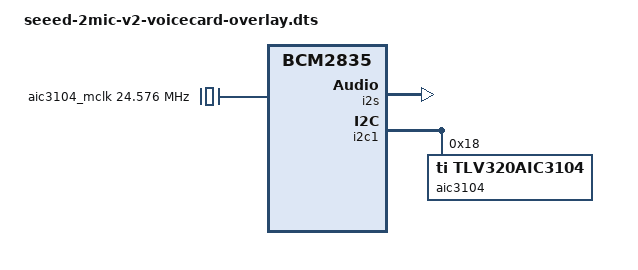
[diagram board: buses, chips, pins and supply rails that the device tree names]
/dts-v1/;
/plugin/;

/*
 * ReSpeaker 2-Mics Pi HAT v2.0 - kernel-independent device tree overlay.
 *
 * The v2 board swapped the WM8960 for a TI TLV320AIC3104 codec on i2c1 at
 * address 0x18 with a 24.576 MHz master clock. Like the v1 overlay, this
 * uses only mainline kernel drivers:
 *   - snd-soc-simple-card    (compatible = "simple-audio-card")
 *   - snd-soc-tlv320aic3x    (compatible = "ti,tlv320aic3104")
 * No out-of-tree kernel module is required, so this works on any kernel
 * >= 5.4 that ships those two modules.
 *
 * Structure follows the v1 overlay (seeed-2mic-voicecard-overlay.dts):
 * new top-level sound node (the Pi's onboard audio keeps working),
 * label-targeted &i2s / &i2c1 so it applies to any base tree exposing
 * __symbols__. Card name is identical ("seeed-2mic-voicecard" -> ALSA
 * card ID "seeed2micvoicec"), so configs and docs are shared between
 * the two HAT versions.
 *
 * CLOCK PLACEMENT NOTE - this is deliberately the OPPOSITE of v1:
 * the tlv320aic3x driver does NOT fetch a clock itself (no
 * devm_clk_get); it receives its sysclk through the set_sysclk DAI op,
 * which simple-card drives from the "clocks" property on the
 * simple-audio-card,codec dai-link subnode. On the v1 wm8960 the clock
 * had to live on the codec device node instead, because that driver
 * reads it with devm_clk_get at probe. Getting this backwards is what
 * caused "No MCLK configured" on v1 - hence this comment.
 *
 * Derived from Seeed Studio's respeaker-2mic-v2_0 overlay (MIT license,
 * Copyright (C) 2024 Seeed Studio) but restructured onto the v1
 * skeleton: Seeed's original replaces the base tree's &sound node
 * (the onboard HDMI audio node), which is unnecessary and risks
 * clobbering onboard audio; it also targets the i2s_clk_consumer
 * symbol, which is just an alias label on the same i2s node this
 * overlay targets.
 *
 * Compile:
 *   dtc -@ -I dts -O dtb -o seeed-2mic-v2-voicecard.dtbo \
 *       seeed-2mic-v2-voicecard-overlay.dts
 */
/ {
	compatible = "brcm,bcm2835";

	/* BCM2835 I2S (PCM) controller, same as v1. The codec is
	 * bitclock/frame master here, so the CPU side runs as clock
	 * consumer - same node either way. */
	fragment@0 {
		target = <&i2s>;
		__overlay__ {
			status = "okay";
		};
	};

	/* Codec master clock: 24.576 MHz fixed clock, referenced from the
	 * dai-link codec subnode below (see CLOCK PLACEMENT NOTE). */
	fragment@1 {
		target-path = "/";
		__overlay__ {
			aic3104_mclk: aic3104_mclk {
				compatible = "fixed-clock";
				#clock-cells = <0>;
				clock-frequency = <24576000>;
			};
		};
	};

	/* TLV320AIC3104 codec on i2c1 at address 0x18. ai3x-micbias-vg = 2
	 * sets MICBIAS to 2.5 V, matching Seeed's v2 overlay (the onboard
	 * electret mics are biased from it). */
	fragment@2 {
		target = <&i2c1>;
		__overlay__ {
			#address-cells = <1>;
			#size-cells = <0>;
			status = "okay";

			aic3104: tlv320aic3104@18 {
				compatible = "ti,tlv320aic3104";
				reg = <0x18>;
				#sound-dai-cells = <0>;
				ai3x-micbias-vg = <2>;
				status = "okay";
			};
		};
	};

	/* The sound card itself: a new top-level node with the same node
	 * name and card name as v1, so PipeWire/PulseAudio sink names and
	 * the ALSA card ID come out identical across HAT revisions. */
	fragment@3 {
		target-path = "/";
		__overlay__ {
			seeed-2mic-sound {
				compatible = "simple-audio-card";
				simple-audio-card,format = "i2s";
				simple-audio-card,name = "seeed-2mic-voicecard";
				status = "okay";

				simple-audio-card,widgets =
					"Headphone", "Headphone Jack",
					"Line", "Line In";
				simple-audio-card,routing =
					"Headphone Jack", "HPLOUT",
					"Headphone Jack", "HPROUT",
					"LINE1L", "Line In",
					"LINE1R", "Line In";

				/* Codec is bitclock/frame master; simple-card
				 * reads mclk from these clocks and programs it
				 * via the aic3x set_sysclk op. */
				simple-audio-card,bitclock-master = <&sound_master>;
				simple-audio-card,frame-master = <&sound_master>;

				simple-audio-card,cpu {
					sound-dai = <&i2s>;
				};

				sound_master: simple-audio-card,codec {
					#sound-dai-cells = <0>;
					sound-dai = <&aic3104>;
					clocks = <&aic3104_mclk>;
					clock-names = "mclk";
				};
			};
		};
	};
};
